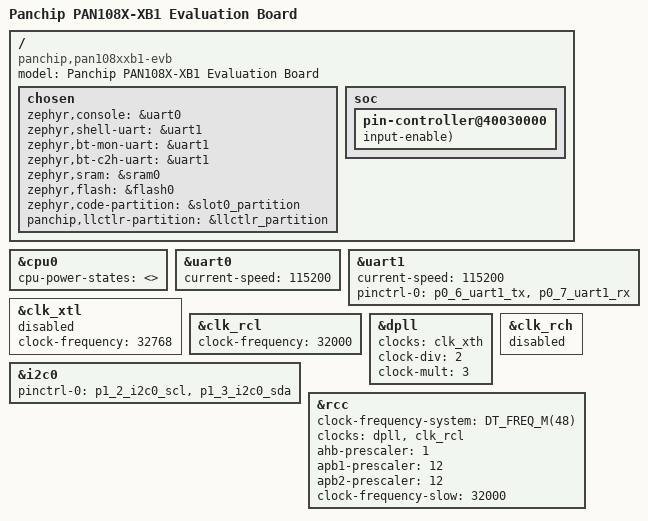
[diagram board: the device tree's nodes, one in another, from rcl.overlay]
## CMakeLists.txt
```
# SPDX-License-Identifier: Apache-2.0

cmake_minimum_required(VERSION 3.20.0)

set(DTC_OVERLAY_FILE "${CMAKE_CURRENT_SOURCE_DIR}/rcl.overlay")

find_package(Zephyr REQUIRED HINTS $ENV{ZEPHYR_BASE})
project(ble_hid_uart)

FILE(GLOB app_sources src/*.c)
target_sources(app PRIVATE
  ${app_sources}
  src/ancs_c.c
  src/i2c_eeprom.c
  src/sc7u22_spi.c
  src/gyroscope.c
  )

zephyr_library_include_directories(${ZEPHYR_BASE}/samples/bluetooth)
```

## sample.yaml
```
sample:
  description: TBD
  name: TBD
tests:
  sample.bluetooth.peripheral_hr:
    harness: bluetooth
    platform_allow: pan1080xxxx
    tags: bluetooth
```

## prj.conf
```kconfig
CONFIG_SIZE_OPTIMIZATIONS=y
CONFIG_IDLE_STACK_SIZE=2048

CONFIG_BT=y
CONFIG_BT_DEBUG_LOG=y
CONFIG_BT_SMP=y
CONFIG_BT_PERIPHERAL=y
CONFIG_BT_DEVICE_NAME="TEST_UART"
CONFIG_BT_DEVICE_APPEARANCE=833
CONFIG_BT_USER_PHY_UPDATE=n
CONFIG_BT_AUTO_PHY_UPDATE=n
CONFIG_BT_PHY_UPDATE=n

# # add #
CONFIG_BT_FIXED_PASSKEY=y
CONFIG_BT_BONDABLE=y

# CONFIG_BT_PRIVACY=y
CONFIG_BT_DIS=y
CONFIG_BT_BAS=y
CONFIG_BT_AUTO_DATA_LEN_UPDATE=n
CONFIG_BT_MAX_PAIRED=2
CONFIG_BT_KEYS_OVERWRITE_OLDEST=y

CONFIG_BT_SETTINGS=y

#
CONFIG_FLASH=y
CONFIG_FLASH_PAGE_LAYOUT=y
CONFIG_FLASH_MAP=y

CONFIG_NVS=y
CONFIG_SETTINGS=y

# debug
CONFIG_BT_DEBUG_SMP=n
CONFIG_BT_SMP_ALLOW_UNAUTH_OVERWRITE=y
# # add #

CONFIG_BT_LL_PREEMPTED_TIME_FOR_ONE_MSEL=400

CONFIG_BT_SET_PUBLIC_MAC=y
CONFIG_BT_USER_DEFINED_PUBLIC_MAC=n
CONFIG_BT_DEVICE_NAME_DYNAMIC=y
CONFIG_FLASH=y

CONFIG_GPIO=y

# # LowPower
# CONFIG_PM=y
# #Clock Source is RCL
# CONFIG_BT_CTLR_SLEEP_CLOCK_SOURCE=1
# #Accuracy is 1000ppm
# CONFIG_BT_CTLR_SLEEP_TIMER_ACCURACY=1000
# #Enable RCL Force CALIBRATION
# CONFIG_SOC_FORCE_CALIB_RCL_CLK=y

# Disable Serial Uart & Log.
# CONFIG_SERIAL=n
# CONFIG_UART_INTERRUPT_DRIVEN=n
# CONFIG_CONSOLE=n
# CONFIG_UART_CONSOLE=n
# CONFIG_PRINTK=n

# CONFIG_BT_DEBUG_CONN=n
# CONFIG_BT_DEBUG_LOG=n

#Enable DC/DC
CONFIG_SOC_DCDC_PAN1080=y
CONFIG_SOC_DCDC_DYNAMICALLY_TUNE_DRIVE_CAPABILITY=n

# CONFIG_BT_CTLR_EVENTS_PRIO=2

#Enbale link layer debug
# CONFIG_BT_CTLR_LINK_LAYER_DEBUG=y

# CONFIG_BT_PERIPHERAL_PREF_MIN_INT=16
# CONFIG_BT_PERIPHERAL_PREF_MAX_INT=16
# CONFIG_BT_PERIPHERAL_PREF_LATENCY=0
# CONFIG_BT_PERIPHERAL_PREF_TIMEOUT=100

# Allow for large Bluetooth data packets.
CONFIG_BT_DATA_LENGTH_EXTENSION=y
CONFIG_BT_DATA_LENGTH_EXTENSION_VALUE=251
#实际发送的数据量是180，因为有三个是帧头


CONFIG_TIMER_READS_ITS_FREQUENCY_AT_RUNTIME=y
CONFIG_REBOOT=y

CONFIG_SYSTEM_WORKQUEUE_STACK_SIZE=1480
CONFIG_ISR_STACK_SIZE=1500
CONFIG_BT_RX_STACK_SIZE=1500

######################  OTA CONFIG  ###########################
# Allow for large Bluetooth data packets.
CONFIG_BT_L2CAP_TX_MTU=252
CONFIG_BT_BUF_ACL_RX_SIZE=256
CONFIG_BT_BUF_ACL_TX_SIZE=251
CONFIG_BT_GATT_CLIENT=y

# Enable the Bluetooth (unauthenticated) and shell mcumgr transports.
CONFIG_MCUMGR_SMP_BT=y
CONFIG_MCUMGR_SMP_BT_AUTHEN=n

# Enable the LittleFS file system.
CONFIG_FILE_SYSTEM=n
CONFIG_FILE_SYSTEM_LITTLEFS=n

# Add 256 bytes to accommodate upload command (lfs_stat overflows)
CONFIG_SYSTEM_WORKQUEUE_STACK_SIZE=2304

# Enable mcumgr.
CONFIG_MCUMGR=y

# Ensure an MCUboot-compatible binary is generated.
CONFIG_BOOTLOADER_MCUBOOT=y

# Required by the `taskstat` command.
CONFIG_THREAD_MONITOR=n

# Enable statistics and statistic names.
CONFIG_STATS=n
CONFIG_STATS_NAMES=n

# Enable most core commands.
CONFIG_MCUMGR_CMD_IMG_MGMT=y
CONFIG_MCUMGR_CMD_OS_MGMT=n
CONFIG_MCUMGR_CMD_STAT_MGMT=n

# Enable spi


CONFIG_PINMUX_PANCHIP=y
CONFIG_CLOCK_CONTROL_PANCHIP=y
CONFIG_SPI=y

CONFIG_I2C=y
###########################################################################
```

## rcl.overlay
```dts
/*
 * Copyright (c) 2020-2022 Shanghai Panchip Microelectronics Co.,Ltd.
 *
 * SPDX-License-Identifier: Apache-2.0
 */

&cpu0 {
	cpu-power-states = <>;
};


/ {
	model = "Panchip PAN108X-XB1 Evaluation Board";
	compatible = "panchip,pan108xxb1-evb", "panchip,pan1080xb1";

	chosen {
		zephyr,console = &uart0;
		zephyr,shell-uart = &uart1;
		zephyr,bt-mon-uart = &uart1;
		zephyr,bt-c2h-uart = &uart1;
		zephyr,sram = &sram0;
		zephyr,flash = &flash0;
		zephyr,code-partition = &slot0_partition;
		panchip,llctlr-partition = &llctlr_partition;
	};
};

&uart0 {
	current-speed = <115200>;
	status = "okay";
};

&uart1 {
	current-speed = <115200>;
	pinctrl-0 = <&p0_6_uart1_tx &p0_7_uart1_rx>;
	status = "okay";
};

&clk_xtl {
	clock-frequency = <32768>;
	/* Enable the 32 KHz low speed crystal oscillator */
	status = "disabled";
};

&clk_rcl {
	clock-frequency = <32000>;
	/* Enable the 32 KHz low speed crystal oscillator */
	status = "okay";
};

&dpll {
	clocks = <&clk_xth>;
	clock-div = <2>;  /* Fixed to 2 */
	clock-mult = <3>; /* Can be 3 (48MHz) or 4 (64MHz) */
	status = "okay";
};

&clk_rch {
	status = "disabled";
};

/ {
	soc {
		pin-controller@40030000 {
			/* I2C0: P12=SCL, P13=SDA */
			DT_PAN_PINS(p1, 2, i2c0_scl, PAN1080_PIN_FUNC_P12_I2C0_SCL, bias-pull-up, input-enable);
			DT_PAN_PINS(p1, 3, i2c0_sda, PAN1080_PIN_FUNC_P13_I2C0_SDA, bias-pull-up, input-enable);
		};
	};
};

&i2c0 {
	pinctrl-0 = <&p1_2_i2c0_scl &p1_3_i2c0_sda>;
	status = "okay";
};

&rcc {
	clock-frequency-system = <DT_FREQ_M(48)>;
	clocks = <&dpll &clk_rcl>;
	ahb-prescaler = <1>;
	apb1-prescaler = <12>;
	apb2-prescaler = <12>;
	clock-frequency-slow = <32000>;
};
```

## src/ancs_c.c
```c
/*
 * Copyright (c) 2023 Shanghai Panchip Microelectronics Co.,Ltd.
 *
 * SPDX-License-Identifier: Apache-2.0
 */

#include <zephyr/types.h>
#include <stddef.h>
#include <errno.h>
#include <zephyr.h>
#include <sys/printk.h>

#include <bluetooth/bluetooth.h>
#include <bluetooth/hci.h>
#include <bluetooth/conn.h>
#include <bluetooth/uuid.h>
#include <bluetooth/gatt.h>
#include <sys/byteorder.h>

#include "ancs_c.h"
#include "controller_ota.h"  // 添加 controller_ota.h 以获取 TGT_SendMultiData 函数声明

extern uint8_t qrcode[100];
extern uint8_t qrcode_length;
extern uint8_t	ANCS_FLAG;	
/**@brief String literals for the iOS notification Category id types. Used then printing to UART. */
static char const *lit_catid[] = {
	"Other",
	"Incoming Call",
	"Missed Call",
	"Voice Mail",
	"Social",
	"Schedule",
	"Email",
	"News",
	"Health And Fitness",
	"Business And Finance",
	"Location",
	"Entertainment"
};

/**@brief String literals for the iOS notification event types. Used then printing to UART. */
static char const *lit_eventid[] = {
	"Added",
	"Modified",
	"Removed"
};

/**@brief String literals for the iOS notification attribute types. Used when printing to UART. */
static char const *lit_attrid[] = {
	"App Identifier",
	"Title",
	"Subtitle",
	"Message",
	"Message Size",
	"Date",
	"Positive Action Label",
	"Negative Action Label"
};
static uint8_t s_attr_buf[CFG_ANCS_ATTRIBUTE_MAXLEN];
static uint16_t s_attr_size;
static uint16_t s_buf_index;
static int s_uid;

struct bt_conn *ancs_c_conn;

static struct bt_uuid_16 uuid = BT_UUID_INIT_16(0);
static struct bt_uuid_128 ancs_srvc_uuid = BT_UUID_INIT_128(ANCS_SRVC_UUID);
static struct bt_uuid_128 ancs_ntf_source_uuid = BT_UUID_INIT_128(ANCS_NTF_SOURCE_UUID);
static struct bt_uuid_128 ancs_control_point_uuid = BT_UUID_INIT_128(ANCS_CONTROL_POINT_UUID);
static struct bt_uuid_128 ancs_data_sourcec_uuid = BT_UUID_INIT_128(ANCS_DATA_SOURCE_UUID);

static uint16_t write_control_point_handle;
static uint16_t ntf_handle;
static uint16_t data_handle;
static struct bt_gatt_write_params write_control_point_params;
static struct bt_gatt_discover_params discover_params;
static struct bt_gatt_subscribe_params subscribe_params_src;
static struct bt_gatt_subscribe_params subscribe_params_data;

static uint8_t notify_source_func(struct bt_conn *conn,
				  struct bt_gatt_subscribe_params *params,
				  const void *data, uint16_t length)
{
	if (!data) {
		printk("[UNSUBSCRIBED]\n");
		params->value_handle = 0U;
		return BT_GATT_ITER_STOP;
	}

	ancs_decode_notification_source((uint8_t *)data, length);

	return BT_GATT_ITER_CONTINUE;
}

static uint8_t notify_data_func(struct bt_conn *conn,
				struct bt_gatt_subscribe_params *params,
				const void *data, uint16_t length)
{
	if (!data) {
		printk("[UNSUBSCRIBED]\n");
		params->value_handle = 0U;
		return BT_GATT_ITER_STOP;
	}

 //	 show_reg3((uint8_t *)data, length);
 ////////************发送变量初始化**********//////////////				
		char send_content[255]={0};
		char *content_copy;
	    char rec_name_type[50] ={0x00};
		uint8_t send_length;
// // ////////************截取软件名字**********//////////////			
        content_copy = (char*)data;		
        send_length = (((uint8_t)content_copy[6]) + (((uint8_t)content_copy[7])<<8));				 	 
//		printf("ancelen=%d\r\n",send_length);
 		memcpy(rec_name_type,&(content_copy[8]),send_length);
// 		printf("rec_name_type=%s\r\n",rec_name_type);
//  ////////************发送软件名字+内容给MCU**********//////////////					 	 	 				        
	    if((bool)strstr(rec_name_type, "com.apple.mobilephone")) 
		{
			char *send_name = "MOBILEPHONE:";
			memcpy(send_content,send_name,12);
		    memcpy(send_content+12,data,length);
			// for(int i=0;i<(length+12);i++)
			// {
			// 	 printf("0x%02x ",send_content[i]);
		    // }
			TGT_SendMultiData((uint8_t *)send_content, length+12);					 
		}
				 
		if((bool)strstr(rec_name_type, "com.tencent.xin")) 
		{
			char *send_name = "WECHAT:";
			memcpy(send_content,send_name,7);
			memcpy(send_content+7,data,length);
			// for(int i=0;i<(length + 7);i++)
		    // {
			// 	printf("0x%02x ",send_content[i]);
			// }					 
			TGT_SendMultiData((uint8_t *)send_content, length+7);	
		}
				 
		if((bool)strstr(rec_name_type, "com.facebook.Facebook")) 
		{
			char *send_name = "FACEBOOK:";
		    memcpy(send_content,send_name,9);
			memcpy(send_content+9,data,length);
			// for(int i=0;i<(param->packet_size + 9);i++)
			// {
			// 	 printf("0x%02x ",send_content[i]);
			// }					 
			TGT_SendMultiData((uint8_t*)send_content, length+9);
		}
				 
		if((bool)strstr(rec_name_type, "com.burbn.instagram")) 
		{
			char *send_name = "INSTAGRAM:";
			memcpy(send_content,send_name,10);
			memcpy(send_content+10,data,length);
			// for(int i=0;i<(length+10);i++)
			// {
			//   printf("0x%02x ",send_content[i]);
			// }					 
			TGT_SendMultiData((uint8_t*)send_content, length+10);
		}
				 
		if((bool)strstr(rec_name_type, "com.atebits.Tweetie2")) 
		{
			char *send_name = "TWITTER:";
			memcpy(send_content,send_name,8);
			memcpy(send_content+8,data,length);
			// for(int i=0;i<(length+8);i++)
		    // {
			// 	printf("0x%02x ",send_content[i]);
			// }					 
			TGT_SendMultiData((uint8_t*)send_content, length+8);
		}				 
 ////////************发送变量初始化**********//////////////	     
 //	ancs_decode_data_source((uint8_t *)data, length);

	return BT_GATT_ITER_CONTINUE;
}

static void write_rsp(struct bt_conn *conn, uint8_t err,
		      struct bt_gatt_write_params *params)
{
	if ((err > 0) && (err != 0xA2) && (err != 0xA3)) {
		printk("write err code 0x%02x\n", err);
	}
}

static uint8_t discover_func(struct bt_conn *conn,
			     const struct bt_gatt_attr *attr,
			     struct bt_gatt_discover_params *params)
{
	int err;

	if (!attr) {
		printk("Discover complete\n");
		(void)memset(params, 0, sizeof(*params));


		return BT_GATT_ITER_STOP;
	}

	printk("[ATTRIBUTE] handle %u\n", attr->handle);

	if (!bt_uuid_cmp(discover_params.uuid, &ancs_srvc_uuid.uuid)) {
		discover_params.uuid = &ancs_control_point_uuid.uuid;
		discover_params.start_handle = attr->handle + 1;
		discover_params.type = BT_GATT_DISCOVER_CHARACTERISTIC;

		err = bt_gatt_discover(conn, &discover_params);
		if (err) {
			printk("Discover failed (err %d)\n", err);
		}
	} else if (!bt_uuid_cmp(discover_params.uuid, &ancs_control_point_uuid.uuid)) {
		write_control_point_handle = attr->handle;
		discover_params.uuid = &ancs_ntf_source_uuid.uuid;
		discover_params.start_handle = attr->handle + 1;
		discover_params.type = BT_GATT_DISCOVER_CHARACTERISTIC;

		err = bt_gatt_discover(conn, &discover_params);
		if (err) {
			printk("Discover failed (err %d)\n", err);
		}
	} else if (!bt_uuid_cmp(discover_params.uuid, &ancs_ntf_source_uuid.uuid)) {
		memcpy(&uuid, BT_UUID_GATT_CCC, sizeof(uuid));
		ntf_handle = attr->handle;
		discover_params.uuid = &uuid.uuid;
		discover_params.start_handle = attr->handle;
		discover_params.type = BT_GATT_DISCOVER_DESCRIPTOR;
		subscribe_params_src.value_handle = bt_gatt_attr_value_handle(attr);

		err = bt_gatt_discover(conn, &discover_params);
		if (err) {
			printk("Discover failed (err %d)\n", err);
		}
	} else if ((!bt_uuid_cmp(discover_params.uuid, BT_UUID_GATT_CCC)) && (attr->handle == (ntf_handle + 2))) {
		subscribe_params_src.notify = notify_source_func;
		subscribe_params_src.value = BT_GATT_CCC_NOTIFY;
		subscribe_params_src.ccc_handle = attr->handle;

		err = bt_gatt_subscribe(conn, &subscribe_params_src);
		if (err && err != -EALREADY) {
			printk("Subscribe failed (err %d)\n", err);
		} else {
			printk("[SUBSCRIBED] %d\n", subscribe_params_src.ccc_handle);
		}

		discover_params.uuid = &ancs_data_sourcec_uuid.uuid;
		discover_params.start_handle = attr->handle + 1;
		discover_params.type = BT_GATT_DISCOVER_CHARACTERISTIC;

		err = bt_gatt_discover(conn, &discover_params);
		if (err) {
			printk("Discover failed (err %d)\n", err);
		}
	} else if (!bt_uuid_cmp(discover_params.uuid, &ancs_data_sourcec_uuid.uuid)) {
		memcpy(&uuid, BT_UUID_GATT_CCC, sizeof(uuid));
		data_handle = attr->handle;
		discover_params.uuid = &uuid.uuid;
		discover_params.start_handle = attr->handle;
		discover_params.type = BT_GATT_DISCOVER_DESCRIPTOR;
		subscribe_params_data.value_handle = bt_gatt_attr_value_handle(attr);

		err = bt_gatt_discover(conn, &discover_params);
		if (err) {
			printk("Discover failed (err %d)\n", err);
		}
	} else if ((!bt_uuid_cmp(discover_params.uuid, BT_UUID_GATT_CCC)) && (attr->handle == (data_handle + 2))) {
		subscribe_params_data.notify = notify_data_func;
		subscribe_params_data.value = BT_GATT_CCC_NOTIFY;
		subscribe_params_data.ccc_handle = attr->handle;

		err = bt_gatt_subscribe(conn, &subscribe_params_data);
		if (err && err != -EALREADY) {
			printk("Subscribe failed (err %d)\n", err);
		} else {
			printk("[SUBSCRIBED] %d\n", subscribe_params_data.ccc_handle);
		}
	}

	return BT_GATT_ITER_STOP;
}

void ble_ancs_c_discovery_service(struct bt_conn *conn)
{
	int err;

	discover_params.uuid = &ancs_srvc_uuid.uuid;
	discover_params.func = discover_func;
	discover_params.start_handle = BT_ATT_FIRST_ATTTRIBUTE_HANDLE;
	discover_params.end_handle = BT_ATT_LAST_ATTTRIBUTE_HANDLE;
	discover_params.type = BT_GATT_DISCOVER_PRIMARY;

	err = bt_gatt_discover(conn, &discover_params);
	if (err) {
		printk("Discover failed(err %d)\n", err);
		return;
	}
}

static void ancs_notify_attr_print(void)
{
	uint8_t commd_id = s_attr_buf[0];
	uint16_t UID;
	uint8_t attr_id;
	uint16_t attr_size = 0;

	memcpy(&UID, &s_attr_buf[1], 4);
	memcpy(&attr_size, &s_attr_buf[6], 2);

	if (commd_id == CTRL_POINT_GET_NTF_ATTRIBUTE) {
		attr_id = s_attr_buf[5];
		printk("UID=%d, ATTR_ID: %s, ATTR_SIZE=%d: ", UID, lit_attrid[attr_id], attr_size);
		for (uint16_t idx = 0; idx < attr_size; idx++) {
			printk("%c", s_attr_buf[8 + idx]);
		}
		printk("\n");
	} else if (commd_id == CTRL_POINT_GET_APP_ATTRIBUTE) {
		for (uint16_t idx = 0; idx < attr_size; idx++) {
			printk("%c", s_attr_buf[idx]);
		}
		printk("\n");
	}
}

void ancs_decode_data_source(uint8_t *p_data, uint16_t length)
{

	//  printk("decode\n");

	/* It's the begginning of a attr info. */
	if (s_buf_index == 0) {
		memcpy(&s_attr_size, &p_data[6], 2);
		memcpy(s_attr_buf, p_data, length);
		/* It's the end of the attr info, a complete attr info is already stored in the buffer. */
		if (s_attr_size == (length - 8)) {
			ancs_notify_attr_print();
			s_buf_index = 0;
		} else {    /* It's not the end of the attr info. */
			s_buf_index = length;
		}
	} else {   /*  It isn't the begginning of a attr info. */
		memcpy(&s_attr_buf[s_buf_index], p_data, length);
		/* It's the end of the attr info, print the buffer. */
		if (s_attr_size == (s_buf_index - 8) + length) {
			ancs_notify_attr_print();
			s_buf_index = 0;
		} else { /* It's not the end of the attr info. */
			s_buf_index = s_buf_index + length;
		}
	}
}

void ancs_set_uid(uint32_t uid)
{
	s_uid = uid;
}

uint32_t ancs_get_uid(void)
{
	return s_uid;
}


void ancs_notify_ctrpoint_get(uint32_t uid)   //获得包括APP名字、发件人、消息内容的详细信息
{
	uint8_t buf[12];

	buf[0] = CTRL_POINT_GET_NTF_ATTRIBUTE;
	memcpy(&buf[1], &uid, 4);
	buf[5] = 0x00;    //APP_ID知道软件名字
  
	
	buf[6] = 0x01;    //title知道发件人名字
	buf[7] = 0xff;
	buf[8] = 0xff; 
	
	buf[9] = 0x03;   //message知道信息内容
	buf[10] = 0xff;
	buf[11] = 0xff; 

    ancs_c_write_control_point(buf,12);  
    //printk("point12=0x%02x 0x%02x 0x%02x 0x%02x 0x%02x 0x%02x 0x%02x 0x%02x 0x%02x 0x%02x 0x%02x 0x%02x",buf[0],buf[1],buf[2],buf[3],buf[4],buf[5],buf[6],buf[7],buf[8],buf[9],buf[10],buf[11]);				

}


void notification_content_print(ntf_source_pdu_t *p_notif)
{
	// // printk("Notification\n");
	// // printk("Event:       %s\n", lit_eventid[p_notif->event_id]);
    // printk("Category ID: %s\n", lit_catid[p_notif->category_id]);
	// printk("Category Cnt:%u\n", p_notif->category_count);
	// // printk("UID:         %u\n", p_notif->notification_uid);
	// // printk("Flags:\n");
	// if (p_notif->event_flags.silent == 1) {
	// 	printk("Silent\n");
	// }
	// if (p_notif->event_flags.important == 1) {
	// 	printk("Important\n");
	// }
	// if (p_notif->event_flags.pre_existing == 1) {
	// 	printk("Pre-existing\n");
	// }
	// if (p_notif->event_flags.positive_action == 1) {
	// 	printk("Positive Action\n");
	// }
	// if (p_notif->event_flags.negative_action == 1) {
	// 	printk("Negative Action\n");
	// }

///////////*************发送ctr_point函数*******////////////////////
	if(strstr(lit_eventid[p_notif->event_id],"Removed"))
	{
        // printk("Removed\n");
	}
	else
	{ 
        // printk("ANCS_FLAG=%d\n",ANCS_FLAG);
	   if(ANCS_FLAG == 3)
	   {
		        // printk("ctrget\n");
		  ancs_notify_ctrpoint_get(p_notif->notification_uid);		
	   }
	}
}

void ancs_decode_notification_source(uint8_t *p_data, uint16_t length)
{
	ntf_source_pdu_t pdu;

    // printk("decode_notification_source\n");

	memcpy(&pdu, p_data, length);
	notification_content_print(&pdu);

	ancs_set_uid((uint32_t) pdu.notification_uid);
}

void ancs_c_write_control_point(uint8_t *p_data, uint16_t length)
{
	write_control_point_params.handle = write_control_point_handle + 1;
	write_control_point_params.func = write_rsp;
	write_control_point_params.offset = 0U;
	write_control_point_params.data = p_data;
	write_control_point_params.length = length;

	if (bt_gatt_write(ancs_c_conn, &write_control_point_params) < 0) {
		printk("write fail\n");
		bt_conn_unref(ancs_c_conn);
	}
}

void ancs_notify_attr_get(uint32_t uid, char noti_attr)
{
	int len = 0;
	uint8_t buf[8];

	buf[0] = CTRL_POINT_GET_NTF_ATTRIBUTE;
	memcpy(&buf[1], &uid, 4);
	buf[5] = noti_attr;

	if ((noti_attr == ANCS_NOTIF_ATTR_ID_TITLE) || (noti_attr == ANCS_NOTIF_ATTR_ID_SUBTITLE)
	    || (noti_attr == ANCS_NOTIF_ATTR_ID_MESSAGE)) {
		len = CFG_ANCS_ATTRIBUTE_MAXLEN;
		buf[6] = (len & 0xff);
		buf[7] = (len >> 8) & 0xff;
		ancs_c_write_control_point(buf, 8);
	} else {
		ancs_c_write_control_point(buf, 6);
	}
}

void ancs_action_perform(uint32_t uid, int action)
{
	uint8_t buf[6];

	buf[0] = CTRL_POINT_PERFORM_NTF_ACTION;
	memcpy(&buf[1], &uid, 4);
	buf[5] = action;
	ancs_c_write_control_point(buf, 6);
}
```

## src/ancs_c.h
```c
/*
 * Copyright (c) 2023 Shanghai Panchip Microelectronics Co.,Ltd.
 *
 * SPDX-License-Identifier: Apache-2.0
 */

#ifndef _ANCS_H_
#define _ANCS_H_

#include <bluetooth/bluetooth.h>
#include <bluetooth/hci.h>
#include <bluetooth/conn.h>
#include <bluetooth/uuid.h>
#include <bluetooth/gatt.h>
#include <sys/byteorder.h>
#include <stdint.h>

/** Maximum allowed value for attribute length */
#ifndef CFG_ANCS_ATTRIBUTE_MAXLEN
#define CFG_ANCS_ATTRIBUTE_MAXLEN 500
#endif

/** Attribute ID element without maximum length */
#define ANCS_ATTR(ID) ((uint32_t) 0x80000000 | ((uint8_t) ID))

/** Attribute ID element with maximum length */
#define ANCS_ATTR_MAXLEN(ID, LEN) ((uint32_t) 0x80000000 | ((uint8_t) ID) | ((uint16_t) LEN << 8))

#define ANCS_SRVC_UUID                       0xd0, 0x00, 0x2d, 0x12, 0x1e, 0x4b, 0x0f, 0xa4, \
	0x99, 0x4e, 0xce, 0xb5, 0x31, 0xf4, 0x05, 0x79                /**< UUID of Apple notification center service. */
#define ANCS_NTF_SOURCE_UUID                 0xbd, 0x1d, 0xa2, 0x99, 0xe6, 0x25, 0x58, 0x8c, \
	0xd9, 0x42, 0x01, 0x63, 0x0d, 0x12, 0xbf, 0x9f                /**< UUID of notification source. */
#define ANCS_CONTROL_POINT_UUID              0xd9, 0xd9, 0xaa, 0xfd, 0xbd, 0x9b, 0x21, 0x98, \
	0xa8, 0x49, 0xe1, 0x45, 0xf3, 0xd8, 0xd1, 0x69                /**< UUID of control point. */
#define ANCS_DATA_SOURCE_UUID                0xfb, 0x7b, 0x7c, 0xce, 0x6a, 0xb3, 0x44, 0xbe, \
	0xb5, 0x4b, 0xd6, 0x24, 0xe9, 0xc6, 0xea, 0x22                /**< UUID of data source. */

/**@brief Event types that are passed from client to application on an event. */
typedef enum {
	BLE_ANCS_C_EVT_INVALID,                /**< ANCS Client invalid event type. */
	BLE_ANCS_C_EVT_DISCOVERY_CPLT,         /**< ANCS Client has found ANCS service and its characteristics. */
	BLE_ANCS_C_EVT_DISCOVERY_FAILED,       /**< ANCS Client found ANCS service failed because of invalid operation or no found at the peer. */
	BLE_ANCS_C_EVT_NTF_SOURCE_NTF_ENABLED, /**< ANCS Client has enable notification for notification source. */
	BLE_ANCS_C_EVT_DATA_SOURCE_NTF_ENABLED,/**< ANCS Client has enable notification for data source. */
	BLE_ANCS_C_EVT_NTF_SOURCE_RECEIVE,     /**< ANCS Client has receive notification from notification source. */
	BLE_ANCS_C_EVT_DATA_SOURCE_RECEIVE,    /**< ANCS Client has receive notification from data source. */
	BLE_ANCS_C_EVT_WRITE_OP_ERR,
} ble_ancs_c_evt_type_t;

/**@brief  ancs handle structure. */
typedef struct {
	uint16_t ancs_service_handle;                   /**< Handle of ancs service as provided by a discovery. */
	uint16_t ancs_ntf_source_handle;                /**< Handle of ancs  notification source characteristic as provided by a discovery. */
	uint16_t ancs_ntf_source_cccd_handle;           /**< Handle of CCCD of ancs  control point characteristic as provided by a discovery. */
	uint16_t ancs_control_point_handle;             /**< Handle of ancs  control point characteristic as provided by a discovery. */
	uint16_t ancs_data_source_handle;               /**< Handle of ancs  data source characteristic as provided by a discovery. */
	uint16_t ancs_data_source_cccd_handle;          /**< Handle of CCCD of ancs data source characteristic as provided by a discovery. */
} ancs_c_att_handles_t;

/**@brief IDs for iOS notification attributes. */
typedef enum {
	ANCS_NOTIF_ATTR_ID_APP_IDENTIFIER = 0,          /**< Identify that the attribute data is of an "App Identifier" type. */
	ANCS_NOTIF_ATTR_ID_TITLE,                       /**< Identify that the attribute data is a "Title". */
	ANCS_NOTIF_ATTR_ID_SUBTITLE,                    /**< Identify that the attribute data is a "Subtitle". */
	ANCS_NOTIF_ATTR_ID_MESSAGE,                     /**< Identify that the attribute data is a "Message". */
	ANCS_NOTIF_ATTR_ID_MESSAGE_SIZE,                /**< Identify that the attribute data is a "Message Size". */
	ANCS_NOTIF_ATTR_ID_DATE,                        /**< Identify that the attribute data is a "Date". */
	ANCS_NOTIF_ATTR_ID_POSITIVE_ACTION_LABEL,       /**< The notification has a "Positive action" that can be executed associated with it. */
	ANCS_NOTIF_ATTR_ID_NEGATIVE_ACTION_LABEL,       /**< The notification has a "Negative action" that can be executed associated with it. */
} ancs_notification_attr_t;

/**@brief Category IDs for iOS notifications. */
typedef enum {
	ANCS_CATEGORY_ID_OTHER,                 /**< The iOS notification belongs to the "other" category.  */
	ANCS_CATEGORY_ID_INCOMING_CALL,         /**< The iOS notification belongs to the "Incoming Call" category. */
	ANCS_CATEGORY_ID_MISSED_CALL,           /**< The iOS notification belongs to the "Missed Call" category. */
	ANCS_CATEGORY_ID_VOICE_MAIL,            /**< The iOS notification belongs to the "Voice Mail" category. */
	ANCS_CATEGORY_ID_SOCIAL,                /**< The iOS notification belongs to the "Social" category. */
	ANCS_CATEGORY_ID_SCHEDULE,              /**< The iOS notification belongs to the "Schedule" category. */
	ANCS_CATEGORY_ID_EMAIL,                 /**< The iOS notification belongs to the "E-mail" category. */
	ANCS_CATEGORY_ID_NEWS,                  /**< The iOS notification belongs to the "News" category. */
	ANCS_CATEGORY_ID_HEALTH_AND_FITNESS,    /**< The iOS notification belongs to the "Health and Fitness" category. */
	ANCS_CATEGORY_ID_BUSINESS_AND_FINANCE,  /**< The iOS notification belongs to the "Buisness and Finance" category. */
	ANCS_CATEGORY_ID_LOCATION,              /**< The iOS notification belongs to the "Location" category. */
	ANCS_CATEGORY_ID_ENTERTAINMENT          /**< The iOS notification belongs to the "Entertainment" category. */
} ancs_category_id_t;

/**@brief Event IDs for iOS notifications. */
typedef enum {
	ANCS_EVENT_ID_NOTIFICATION_ADDED,       /**< The iOS notification was added. */
	ANCS_EVENT_ID_NOTIFICATION_MODIFIED,    /**< The iOS notification was modified. */
	ANCS_EVENT_ID_NOTIFICATION_REMOVED      /**< The iOS notification was removed. */
} ancs_evt_id_t;

/**@brief ID for actions that can be performed for iOS notifications. */
typedef enum {
	ACTION_ID_POSITIVE = 0,                 /**< Positive action. */
	ACTION_ID_NEGATIVE                      /**< Negative action. */
} ancs_c_action_id_t;

/**@brief ctrl point command that can be performed for iOS notifications. */
typedef enum {
	CTRL_POINT_GET_NTF_ATTRIBUTE = 0,/**< Request attributes to be sent from the NP to the NC for a given notification. */
	CTRL_POINT_GET_APP_ATTRIBUTE,    /**< Request attributes to be sent from the NP to the NC for a given iOS app. */
	CTRL_POINT_PERFORM_NTF_ACTION,   /**< Request an action to be performed on a given notification, for example, dismiss an alarm. */
} ancs_c_ctrl_point_t;


/**@brief notification flags that can be performed for iOS notifications. */
typedef struct {
	uint8_t silent          : 1;            /**< If this flag is set, the notification has a low priority. */
	uint8_t important       : 1;            /**< If this flag is set, the notification has a high priority. */
	uint8_t pre_existing    : 1;            /**< If this flag is set, the notification is pre-existing. */
	uint8_t positive_action : 1;            /**< If this flag is set, the notification has a positive action that can be taken. */
	uint8_t negative_action : 1;            /**< If this flag is set, the notification has a negative action that can be taken. */
} ancs_ntf_flags_t;

/**@brief iOS notification structure. */
typedef struct {
	ancs_evt_id_t event_id;                 /**< Whether the notification was added, removed, or modified. */
	ancs_ntf_flags_t event_flags;           /**< Whether the notification was added, removed, or modified. */
	ancs_category_id_t category_id;         /**< Classification of the notification type, for example, email or location. */
	uint8_t category_count;                 /**< Current number of active notifications for this category ID. */
	uint32_t notification_uid;              /**< Notification UID. */
} ntf_source_pdu_t;


extern struct bt_conn *ancs_c_conn;

/**
 *****************************************************************************************
 * @brief To access phone's all services about ANCS.
 *****************************************************************************************
 */
void ble_ancs_c_discovery_service(struct bt_conn *conn);

/**
 *****************************************************************************************
 * @brief Decode notification source message.
 *
 * @param[in] p_data: Pointer to the parameters of the read request.
 * @param[in] length: The Length of read value
 *****************************************************************************************
 */
void ancs_decode_notification_source(uint8_t *p_data, uint16_t length);

/**
 *****************************************************************************************
 * @brief Decode data source message.
 *
 * @param[in] p_data: Pointer to the parameters of the read request.
 * @param[in] length: Length of read data
 *****************************************************************************************
 */
void ancs_decode_data_source(uint8_t *p_data, uint16_t length);

/**
 *****************************************************************************************
 * @brief Get notification attribute
 *
 * @param[in] uid: The UID of notify message
 * @param[in] noti_attr: The notification attribute
 *
 *****************************************************************************************
 */
void ancs_notify_attr_get(uint32_t uid, char noti_attr);

/**
 *****************************************************************************************
 * @brief ancs perform action
 *
 * @param[in] uid: The UID of notify message
 * @param[in] action: The action status defined by specification
 *
 *****************************************************************************************
 */
void ancs_action_perform(uint32_t uid, int action);

/**
 *****************************************************************************************
 * @brief set phone call notify message uid
 *
 * @param[in] uid: the uid of notify message
 *****************************************************************************************
 */
void ancs_set_uid(uint32_t uid);

/**
 *****************************************************************************************
 * @brief get ancs phone call UID
 *
 * @return phone call notify message UID
 *****************************************************************************************
 */
uint32_t ancs_get_uid(void);

///获取APP_ID软件名字、title发件人名字、message信息内容///
void ancs_notify_ctrpoint_get(uint32_t uid);
///获取APP_ID软件名字、title发件人名字、message信息内容///

#endif
```

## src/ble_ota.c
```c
#include "ble_ota.h"
#include "mcu_to_ble_protocol_v3.0.h"
#include "i2c_eeprom.h"
#include "controller_ota.h"
#include <string.h>
#include <sys/printk.h>

extern int bt_ven_notify(uint8_t *data, uint32_t len);

static OtaContext g_ota_ctx;

/* ── CRC functions ─────────────────────────────────────────────── */

static uint32_t OtaFileCrcCalculate(const uint8_t *content, uint32_t len)
{
	uint32_t crc = 0;
	uint8_t  buf[4];

	for (uint32_t i = 0; i < len; i += 4) {
		uint32_t data;
		if (i + 4 <= len)
		{
			data = *(const uint32_t *)(content + i);
		}
		else
		{
			buf[0] = buf[1] = buf[2] = buf[3] = 0xFF;
			for (uint32_t j = 0; i + j < len; j++) {
				buf[j] = content[i + j];
			}
			data = *(const uint32_t *)buf;
		}
		crc ^= data;
	}
	return crc;
}

static uint8_t Ota_Packet_CrcCalculate(const uint8_t *data, uint32_t len)
{
	uint8_t crc = 0;
	for (uint32_t i = 0; i < len; i++)
	{
		crc ^= data[i];
	}
	return crc;
}

/* ── Response builders ─────────────────────────────────────────── */

static void OtaSendStartResponse(uint8_t result)
{
	uint8_t frame[OTA_FRAME_START_RSP_SIZE];
	frame[0] = V3_FRAME_HEAD_0;
	frame[1] = V3_FRAME_HEAD_1;
	frame[2] = OTA_CMD_START;
	frame[3] = OTA_FRAME_START_RSP_SIZE;
	frame[4] = result;
	bt_ven_notify(frame, OTA_FRAME_START_RSP_SIZE);
	printk("[OTA] Start response sent, result=0x%02X\n", result);
}

static void OtaSendFlashEraseDone(uint8_t result)
{
	uint8_t frame[OTA_FRAME_FLASH_ERASE_RSP_SIZE];
	frame[0] = V3_FRAME_HEAD_0;
	frame[1] = V3_FRAME_HEAD_1;
	frame[2] = OTA_CMD_FLASH_ERASE_DONE;
	frame[3] = OTA_FRAME_FLASH_ERASE_RSP_SIZE;
	frame[4] = result;
	bt_ven_notify(frame, OTA_FRAME_FLASH_ERASE_RSP_SIZE);
	printk("[OTA] Flash erase done sent, result=0x%02X\n", result);
}

static void OtaSendDataAck(uint16_t seq, uint8_t result)
{
	uint8_t frame[OTA_FRAME_DATA_ACK_SIZE];
	frame[0] = V3_FRAME_HEAD_0;
	frame[1] = V3_FRAME_HEAD_1;
	frame[2] = OTA_CMD_DATA;
	frame[3] = OTA_FRAME_DATA_ACK_SIZE;
	frame[4] = (uint8_t)(seq & 0xFF);
	frame[5] = (uint8_t)((seq >> 8) & 0xFF);
	frame[6] = result;
	bt_ven_notify(frame, OTA_FRAME_DATA_ACK_SIZE);
	printk("[OTA] Data ACK seq=%u result=0x%d\n", seq, result);
}

static void OtaSendPackageRetryAck(uint8_t result)
{
	uint8_t frame[OTA_FRAME_FLASH_ERASE_RSP_SIZE];
	frame[0] = V3_FRAME_HEAD_0;
	frame[1] = V3_FRAME_HEAD_1;
	frame[2] = OTA_CMD_DATA_RETRY;
	frame[3] = OTA_FRAME_FLASH_ERASE_RSP_SIZE;
	frame[4] = result;
	bt_ven_notify(frame, OTA_FRAME_DATA_ACK_SIZE);
	printk("[OTA] Retry result=0x%02X\n", result);
}

static void OtaSendEraseRetryAck(uint8_t result)
{
	uint8_t frame[OTA_FRAME_FLASH_ERASE_RSP_SIZE];
	frame[0] = V3_FRAME_HEAD_0;
	frame[1] = V3_FRAME_HEAD_1;
	frame[2] = OTA_CMD_ERASE_RETRY;
	frame[3] = OTA_FRAME_FLASH_ERASE_RSP_SIZE;
	frame[4] = result;
	bt_ven_notify(frame, OTA_FRAME_DATA_ACK_SIZE);
	printk("[OTA] Erase Retry result=0x%02X\n", result);
}
/* ── Incremental file CRC helpers ───────────────────────────────── */

static void OtaFileCrcReset(void)
{
	g_ota_ctx.running_crc = 0;
	g_ota_ctx.crc_partial_word = 0;
	g_ota_ctx.crc_partial_shift = 0;
}

/*
data:文件包
len:文件包长度
OtaFileCrcUpdate:对整个文件包进行CRC校验计算，便于后续与整个文件的CRC作对比，验证准确性
*/
static void OtaFileCrcUpdate(const uint8_t *data, uint32_t len)
{
	uint32_t *p = &g_ota_ctx.crc_partial_word;
	uint8_t  *s = &g_ota_ctx.crc_partial_shift;

	for (uint32_t i = 0; i < len; i++)
	{
		*p |= (uint32_t)data[i] << *s;
		*s += 8;
		if (*s == 32) {
			g_ota_ctx.running_crc ^= *p;
			*p = 0;
			*s = 0;
		}
	}
}

static uint32_t OtaFileCrcFinalize(void)
{
	uint32_t *p = &g_ota_ctx.crc_partial_word;
	uint8_t  *s = &g_ota_ctx.crc_partial_shift;

	if (*s > 0)
	{
		while (*s < 32)
		{
			*p |= (uint32_t)0xFF << *s;
			*s += 8;
		}
		g_ota_ctx.running_crc ^= *p;
		*p = 0;
		*s = 0;
	}
	return g_ota_ctx.running_crc;
}

/* ── Public API ────────────────────────────────────────────────── */

void Ota_init(void)
{
	memset(&g_ota_ctx, 0, sizeof(g_ota_ctx));
	g_ota_ctx.state = OTA_STATE_IDLE;
	printk("[OTA] Module initialized\n");
}
//处理APP发送的OTA请求
void OtaHandleStartRequest(const uint8_t *frame)
{
	if (g_ota_ctx.state != OTA_STATE_IDLE)
	{

		 printk("igorned [OTA] is in progress\n ");
		 return;
	}
	uint8_t flag = 0;
	EepromWrite(CTRL_OTA_FLAG_ADDR, &flag, 1);//在下载数据的时候清除OTA标志位，防止控制器无回复，单CRC错误，长度不对情况下更新文件时控制器的OTA同时进行

	uint32_t file_len = (uint32_t)frame[4]
	                  | ((uint32_t)frame[5] << 8)
	                  | ((uint32_t)frame[6] << 16)
	                  | ((uint32_t)frame[7] << 24);

	uint32_t file_crc = (uint32_t)frame[8]
	                  | ((uint32_t)frame[9] << 8)
	                  | ((uint32_t)frame[10] << 16)
	                  | ((uint32_t)frame[11] << 24);

	printk("[OTA] Start request: file_len=%u, file_crc=0x%08X\n", file_len, file_crc);

	if (file_len == 0)
	{
		printk("[OTA] Invalid file length\n");
		OtaSendStartResponse(OTA_RESULT_FAIL);
		OtaReset();
		return;
	}

	if (file_len > CTRL_OTA_FLAG_ADDR)
	{
		printk("[OTA] File too large: %u > %u\n", file_len, (EEPROM_SIZE - EEPROM_PAGE_SIZE));
		OtaSendStartResponse(OTA_RESULT_FAIL);
		OtaReset();
		return;
	}

	g_ota_ctx.file_length = file_len;
	g_ota_ctx.file_crc = file_crc;
	g_ota_ctx.state = OTA_STATE_START_RECEIVED;

	OtaSendStartResponse(OTA_RESULT_SUCCESS);

	g_ota_ctx.state = OTA_STATE_ERASING;
	EepromErase(OTA_EEPROM_BASE_ADDR, file_len);

	g_ota_ctx.state = OTA_STATE_RECEIVING;
	g_ota_ctx.eeprom_addr = OTA_EEPROM_BASE_ADDR;
	g_ota_ctx.expected_seq = 0;
	g_ota_ctx.received_length = 0;
	g_ota_ctx.resend_count = 0;
	OtaFileCrcReset();
	printk("[OTA] start to ERASE\n");

	OtaSendFlashEraseDone(OTA_RESULT_SUCCESS);
	printk("[OTA] Ready to receive data\n");
}

// static uint8_t test_data = 0;
//APP发送的数据包处理逻辑
void OtaHandleDataPacket(const uint8_t *frame, uint16_t frame_len)
{
	if (g_ota_ctx.state != OTA_STATE_RECEIVING)
	{
		printk("[OTA] Data packet ignored, state=%d\n", g_ota_ctx.state);
		return;
	}

	if (frame_len < OTA_FRAME_DATA_MIN_SIZE || frame_len > OTA_FRAME_DATA_MAX_SIZE)
	{
		printk("[OTA] Invalid data frame length %u\n", frame_len);
		return;
	}

	/*小端，先验证包序号*/
	uint16_t seq = (uint16_t)frame[4] | ((uint16_t)frame[5] << 8);

	// if(seq == 0x63 && test_data == 0)
	// {
	// 	g_ota_ctx.expected_seq = g_ota_ctx.expected_seq + 1;
	// 	test_data ++;
	// }
	// else if (seq == 0x63 && test_data == 1 )
	// {
	// 	g_ota_ctx.expected_seq = g_ota_ctx.expected_seq -1;
	// }
	if (seq != g_ota_ctx.expected_seq)
	{
		printk("[OTA] Seq mismatch: expected=%u got=%u\n", g_ota_ctx.expected_seq, seq);
		g_ota_ctx.resend_count++;
		if (g_ota_ctx.resend_count >= OTA_MAX_RESEND_COUNT)
		{
			printk("[OTA] seq error %d\n",seq);
			g_ota_ctx.state = OTA_STATE_ERROR;
			OtaSendDataAck(seq, OTA_ACK_FAIL);
			OtaReset();
		}
		else
		{
			OtaSendDataAck(seq, OTA_ACK_RESEND);
		}
		return;
	}

	/*
	实际数据包长度-8字节
	实际包内容从第七字节开始
	*/
	uint16_t content_len = frame_len - 8;
	const uint8_t *content = frame + 7;

	/* 验证CRC */
	uint8_t computed_crc = Ota_Packet_CrcCalculate(content, content_len);
	uint8_t received_crc = frame[frame_len - 1];
	// if(test_data == 1)
	// {
	// 	computed_crc++;
	// 	test_data++;
	// }
	// else
	// {
	// 	computed_crc = Ota_Packet_CrcCalculate(content, content_len);
	// }
	if (computed_crc != received_crc)
	{
		printk("[OTA] Packet CRC mismatch: calc=0x%02X recv=0x%02X\n", computed_crc, received_crc);
		g_ota_ctx.resend_count++;
		if (g_ota_ctx.resend_count >= OTA_MAX_RESEND_COUNT)
		{
			printk("[OTA] Too many resends, aborting\n");
			g_ota_ctx.state = OTA_STATE_ERROR;
			OtaSendDataAck(g_ota_ctx.expected_seq, OTA_ACK_FAIL);//10次OTA都失败，传输03错误
			OtaReset();
		}
		else
		{
			OtaSendDataAck(g_ota_ctx.expected_seq, OTA_ACK_RESEND);
		}
		return;
	}

	/* 是否是尾包 00最后一包,01继续*/
	uint8_t has_more = frame[6];

	printk("[OTA] Data packet seq=%u hasMore=%u frameLen=%u\n", seq, has_more, frame_len);



	uint32_t remaining = g_ota_ctx.file_length - g_ota_ctx.received_length;
	uint16_t valid_len = (content_len <= remaining) ? content_len : (uint16_t)remaining;

	if (valid_len > 0)
	{
		/* 写数据包至EEPROM */
		EepromWrite(g_ota_ctx.eeprom_addr, content, valid_len);

		/* 更新总文件的四字节CRC*/
		OtaFileCrcUpdate(content, valid_len);

		g_ota_ctx.eeprom_addr += valid_len;
		g_ota_ctx.received_length += valid_len;
	}

	g_ota_ctx.expected_seq++;		//包序号自增
	g_ota_ctx.resend_count = 0;		//重置重发次数

	/*是否是最后一包*/
	if (has_more == 0x00)
	{
		uint32_t final_crc = OtaFileCrcFinalize();
		printk("[OTA] Last packet, file CRC calc=0x%08X expected=0x%08X\n", final_crc, g_ota_ctx.file_crc);

		if (final_crc == g_ota_ctx.file_crc)
		{
			g_ota_ctx.state = OTA_STATE_COMPLETE;
			printk("[OTA] Download complete, CRC OK\n");
			OtaSendDataAck(seq, OTA_ACK_CONTINUE);

			//OTA标质量置1，总存储文件长度及CRC
			Ctrl_ota_setota_readyflag(g_ota_ctx.file_length, g_ota_ctx.file_crc);
		}
		else
		{
			printk("[OTA] File CRC mismatch\n");
			printk("APP_CRC_RESULT %x\r\n", g_ota_ctx.file_crc);
			printk("BLE_CRC_RESULT %x\r\n", final_crc);
			OtaSendDataAck(seq, OTA_ACK_FAIL);
		}
		OtaReset();
		return;
	}

	/* ACK to continue */
	OtaSendDataAck(seq, OTA_ACK_CONTINUE);
}

//重置整个EEMPROM的数据包，从头0000开始存，但是总文件大小不变
void OtaPackageRetry(const uint8_t *frame)
{
	if (frame[4] == 0x0E)
	{
		g_ota_ctx.state = OTA_STATE_ERASING;
		EepromErase(OTA_EEPROM_BASE_ADDR, g_ota_ctx.file_length);

		g_ota_ctx.state = OTA_STATE_RECEIVING;
		g_ota_ctx.eeprom_addr = OTA_EEPROM_BASE_ADDR;
		g_ota_ctx.expected_seq = 0;
		g_ota_ctx.received_length = 0;
		g_ota_ctx.resend_count = 0;
		OtaFileCrcReset();
		OtaSendPackageRetryAck(OTA_RESULT_SUCCESS);
		printk("[OTA] Package Retry\n");
	}
	else
	{
		OtaSendPackageRetryAck(OTA_RESULT_FAIL);
	}
}

//重置OTA状态，恢复成默认值，可以重新擦除
void OtaEraseRetry(const uint8_t *frame)
{
	if (frame[4] == 0x09)
	{
		g_ota_ctx.state = OTA_STATE_IDLE;//重置OTA状态，
		printk("[OTA] Erase Retry\n");
		OtaSendEraseRetryAck(OTA_RESULT_SUCCESS);

	}
	else
	{
		OtaSendEraseRetryAck(OTA_RESULT_FAIL);
	}
}

void OtaReset(void)
{
	memset(&g_ota_ctx, 0, sizeof(g_ota_ctx));
	g_ota_ctx.state = OTA_STATE_IDLE;
	printk("[OTA] State reset to IDLE\n");
}

bool OtaIsInProgress(void)
{
	return (g_ota_ctx.state != OTA_STATE_IDLE);
}
```

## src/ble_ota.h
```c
#ifndef BLE_OTA_H
#define BLE_OTA_H

#include <stdint.h>
#include <stdbool.h>

/* OTA Command Codes */
#define OTA_CMD_START             0x06
#define OTA_CMD_FLASH_ERASE_DONE  0x07
#define OTA_CMD_DATA              0x08
#define OTA_CMD_DATA_RETRY	  0x0B
#define OTA_CMD_ERASE_RETRY       0x0C

/* OTA Frame Sizes */
#define OTA_FRAME_START_REQ_SIZE  12
#define OTA_FRAME_START_RSP_SIZE  5
#define OTA_FRAME_FLASH_ERASE_RSP_SIZE  5
#define OTA_FRAME_DATA_ACK_SIZE   7
#define OTA_FRAME_DATA_MIN_SIZE   8
#define OTA_FRAME_DATA_MAX_SIZE   208

/* OTA Data Constraints */
#define OTA_DATA_MAX_CONTENT      200

/* OTA Result Codes */
#define OTA_RESULT_SUCCESS        0x01
#define OTA_RESULT_FAIL           0x02
#define OTA_ACK_CONTINUE          0x01
#define OTA_ACK_RESEND            0x02
#define OTA_ACK_FAIL              0x03

/* OTA EEPROM Base Address (configurable) */
#define OTA_EEPROM_BASE_ADDR      0x0000

/* Max resend retries before abort */
#define OTA_MAX_RESEND_COUNT      10

/* OTA State */
typedef enum {
	OTA_STATE_IDLE = 0,
	OTA_STATE_START_RECEIVED,
	OTA_STATE_ERASING,
	OTA_STATE_RECEIVING,
	OTA_STATE_COMPLETE,
	OTA_STATE_ERROR,
} OtaState;

/* OTA Context */
typedef struct {
	OtaState state;
	uint32_t file_length;			//文件总长度
	uint32_t file_crc;
	uint32_t received_length;
	uint32_t running_crc;			//总crc校验
	uint16_t expected_seq;			//包序号
	uint32_t eeprom_addr;			//eeprom地址
	uint8_t  resend_count;			//重发次数
	uint32_t crc_partial_word;		//包crc字节
	uint8_t  crc_partial_shift;		//包crc偏移量
} OtaContext;

/* Public API */
void Ota_init(void);
void OtaHandleStartRequest(const uint8_t *frame);
void OtaHandleDataPacket(const uint8_t *frame, uint16_t frame_len);
void OtaReset(void);
void OtaPackageRetry(const uint8_t *frame);
void OtaEraseRetry(const uint8_t *frame);
bool OtaIsInProgress(void);



#endif /* BLE_OTA_H */
```

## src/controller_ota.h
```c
#ifndef CONTROLLER_OTA_H
#define CONTROLLER_OTA_H

#include <stdint.h>
#include <stdbool.h>
#include <stddef.h>
#include "i2c_eeprom.h"

/* ── EEPROM layout (last page, 256 bytes at ) ──────────── */
#define CTRL_OTA_FLAG_ADDR      (EEPROM_SIZE - EEPROM_PAGE_SIZE)
#define CTRL_OTA_META_FILE_LEN  (CTRL_OTA_FLAG_ADDR + 1)
#define CTRL_OTA_META_FILE_CRC  (CTRL_OTA_FLAG_ADDR + 5)

#define CTRL_OTA_FLAG_READY     0x01
#define CTRL_OTA_FLAG_IDLE      0x00

/* ── Protocol frame header ──────────────────────────────────── */
#define CTRL_OTA_HEAD_BYTE      0xEB
#define CTRL_OTA_HEAD_BYTE2     0x90
#define CTRL_OTA_HDR_LEN        6


/* ── Downlink commands (BLE → Controller) ──────────────────── */
#define CTRL_CMD_WRITE_REQ      0x06
#define CTRL_CMD_VERIFY_REQ     0x05
#define CTRL_CMD_DATA           0x2B

/* ── BLE → APP notification commands (V3 frame) ───────────── */
#define CTRL_OTA_V3_PROGRESS     0x09   /* 53 35 09 05 XX */
#define CTRL_OTA_V3_RESULT       0x0A   /* 53 35 0A 05 XX */
#define CTRL_OTA_RESULT_OK       0x01
#define CTRL_OTA_RESULT_ERROR    0x02
#define CTRL_OTA_RESULT_FAILED	 0x03

/* ── Uplink commands (Controller → BLE) ────────────────────── */
#define CTRL_CMD_REQ_CONFIRM    0x07
#define CTRL_CMD_FLASH_ERASE_OK 0x17
#define CTRL_CMD_DATA_ACK       0x0B
#define CTRL_CMD_RECV_COMPLETE  0x08
#define CTRL_CMD_CRC_SUCCESS    0x0C
#define CTRL_CMD_CRC_FAIL       0x0D
#define CTRL_CMD_CRC_ERROR      0x09
#define CTRL_CMD_LEN_ERROR      0x0A

/* ── Frame sizes ────────────────────────────────────────────── */
#define CTRL_REQ_FRAME_LEN      16   /* HDR(6)+LEN(1)+CMD(1)+fileLen(4)+fileCrc(4) */
#define CTRL_RSP_FRAME_LEN      8    /* HDR(6)+LEN(1)+CMD(1) */
#define CTRL_DATA_HDR_OVERHEAD  10   /* HDR(6)+LEN(1)+CMD(1)+hasMore(1)+CRC(1) */
#define CTRL_DATA_MAX_PAYLOAD   200

/* ── State machine ──────────────────────────────────────────── */
typedef enum {
	CTRL_OTA_IDLE = 0,
	CTRL_OTA_SEND_REQUEST,
	CTRL_OTA_WAIT_CONFIRM,
	CTRL_OTA_SEND_DATA,
	CTRL_OTA_WAIT_DATA_ACK,
	CTRL_OTA_WAIT_COMPLETE,
	CTRL_OTA_COMPLETE,
	CTRL_OTA_ERROR,
	CTRL_OTA_FILED,
} CtrlOtaState;

/* ── Public API ─────────────────────────────────────────────── */
void Ctrl_ota_init(void);
void Ctrl_ota_process(void);
bool Ctrl_ota_is_active(void);
void Ctrl_ota_handle_reply(uint8_t cmd);
void Ctrl_ota_setota_readyflag(uint32_t file_length, uint32_t file_crc);

extern void TGT_SendMultiData(const uint8_t *data, size_t size);
extern int bt_ven_notify(uint8_t *data, uint32_t len);



#endif /* CONTROLLER_OTA_H */
```

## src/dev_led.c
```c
#include "dev_led.h"
#include <devicetree.h>
#include <drivers/gpio.h>

#define LED0_NODE DT_ALIAS(led0)
#define LED1_NODE DT_ALIAS(led1)
static const struct gpio_dt_spec led_red = GPIO_DT_SPEC_GET(LED0_NODE, gpios);
static const struct gpio_dt_spec led_green = GPIO_DT_SPEC_GET(LED1_NODE, gpios);

static const struct device *led_dev;
static struct k_timer led_timer;
static led_state_t led_state = LED_STATE_OFF;
static bool led_blink_on = false;

// 定时器回调函数，用于控制LED状态
static void led_timer_cb(struct k_timer *timer)
{
    static uint8_t shine_counts = 0;
    switch (led_state) {
        case LED_STATE_GREEN_ON: // 绿灯常亮
            gpio_pin_set_dt(&led_green, 0); // 绿灯亮
            gpio_pin_set_dt(&led_red, 1);  // 红灯灭
            break;
        case LED_STATE_RED_ON: // 红灯常亮
            gpio_pin_set_dt(&led_green, 1); // 绿灯灭
            gpio_pin_set_dt(&led_red, 0);  // 红灯亮
            break;
        case LED_STATE_RED_FAST_BLINK: // 红灯快闪
            gpio_pin_set_dt(&led_green, 1);
            gpio_pin_set_dt(&led_red, led_blink_on ? 0 : 1);
            led_blink_on = !led_blink_on;
            k_timer_start(&led_timer, K_MSEC(50), K_NO_WAIT);
            break;
        case LED_STATE_RED_SLOW_BLINK: // 红灯慢闪
            gpio_pin_set_dt(&led_green, 1);
            gpio_pin_set_dt(&led_red, led_blink_on ? 0 : 1);
            led_blink_on = !led_blink_on;
            k_timer_start(&led_timer, K_MSEC(200), K_NO_WAIT);
            break;
	case LED_STATE_GREEN_FAST_BLINK://绿灯快速闪烁
	    gpio_pin_set_dt(&led_green, led_blink_on ? 0 : 1);
	    led_blink_on = !led_blink_on;
            k_timer_start(&led_timer, K_MSEC(50), K_NO_WAIT);
	    shine_counts++;
	    if(shine_counts >=30)
	    {
		shine_counts = 0;
		led_state = LED_STATE_OFF;
	    }
	    break;
	default: // 默认，亮绿灯 正常工作
		gpio_pin_set_dt(&led_green, 0);
		gpio_pin_set_dt(&led_red, 1);
		break;
	}
}

// 设置LED状态
void set_led_state(led_state_t state)
{
    led_state = state;
    led_blink_on = false;
    // 立即刷新一次
    k_timer_start(&led_timer, K_NO_WAIT, K_MSEC(500));
}

// 初始化LED
void user_led_init(void)
{
//     gpio_pin_configure_dt(&led_red, GPIO_OUTPUT_ACTIVE);
    gpio_pin_configure_dt(&led_green, GPIO_OUTPUT_ACTIVE);
//     gpio_pin_set_dt(&led_red, 1);  // 红灯灭
    gpio_pin_set_dt(&led_green, 1); // 绿灯灭

    k_timer_init(&led_timer, led_timer_cb, NULL);
    //set_led_state(LED_STATE_GREEN_ON);

    printk("user_led_init init done \n");
}
```

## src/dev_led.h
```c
#ifndef DEV_LED_H
#define DEV_LED_H

#include <zephyr.h>
#include <device.h>
#include <drivers/gpio.h>

typedef enum {
    LED_STATE_OFF = 0,
    LED_STATE_GREEN_ON,
    LED_STATE_RED_ON,
    LED_STATE_RED_FAST_BLINK,
    LED_STATE_RED_SLOW_BLINK,
    LED_STATE_GREEN_FAST_BLINK
} led_state_t;

void user_led_init(void);
void set_led_state(led_state_t state);

#endif // DEV_LED_H
```

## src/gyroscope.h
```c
#ifndef _GYROSCOPE_H_
#define _GYROSCOPE_H_

#include <stdint.h>

/*
 * 陀螺仪应用层 - 移植自原工程 User/inc/Gyroscope.h
 *
 * 依赖: sc7u22_spi.c (传感器驱动 + PWM输出)
 */

/* 角度输出结构体 (对应原工程 Gyroscope.h:33-37) */
typedef struct {
	float Angle; /* pitch 角度, 单位:度 */
} tsGyroscope;

/* 全局变量 (对应原工程 Gyroscope.h:49-52) */
extern tsGyroscope Gyroscope;
extern float Q_ANGLE_X, Q_ANGLE_Y, Q_ANGLE_Z;
extern uint8_t flag_gyro;

/* API (对应原工程 Gyroscope.h:53-55) */
void GyroscopeInit(void);
void GyrosCopeDataRead(void);

#endif /* _GYROSCOPE_H_ */
```

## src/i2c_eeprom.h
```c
#ifndef _I2C_EEPROM_H_
#define _I2C_EEPROM_H_

#include <stdint.h>

#ifdef __cplusplus
extern "C" {
#endif

#define EEPROM_I2C_BASE_ADDR_7BIT  0x50
#define EEPROM_PAGE_SIZE           256
#define EEPROM_SIZE                (256U * 512U)

void I2c_eeprom_init(void);

/* EEPROM stub functions (user to implement) */
void EepromErase(uint32_t addr, uint32_t size);
void EepromWrite(uint32_t addr, const uint8_t *data, uint32_t len);
void EepromRead(uint32_t addr, uint8_t *data, uint32_t len);
#ifdef __cplusplus
}
#endif

#endif /* _I2C_EEPROM_H_ */
```
